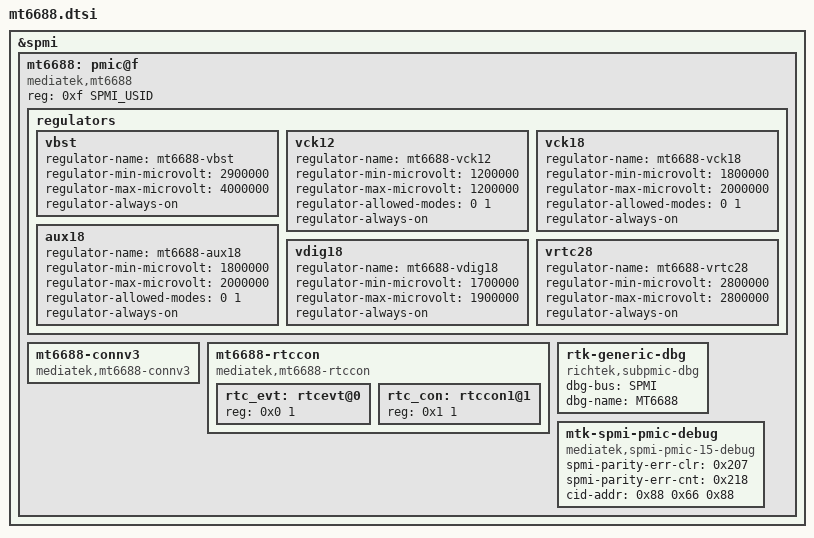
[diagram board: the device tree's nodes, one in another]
// SPDX-License-Identifier: GPL-2.0
/*
 * Copyright (c) 2024 MediaTek Inc.
 */
#include <dt-bindings/spmi/spmi.h>

&spmi {
	mt6688: pmic@f {
		compatible = "mediatek,mt6688";
		reg = <0xf SPMI_USID>;

		regulators {
			vbst {
				regulator-name = "mt6688-vbst";
				regulator-min-microvolt = <2900000>;
				regulator-max-microvolt = <4000000>;
				regulator-always-on;
			};
			vck12 {
				regulator-name = "mt6688-vck12";
				regulator-min-microvolt = <1200000>;
				regulator-max-microvolt = <1200000>;
				regulator-allowed-modes = <0 1>;
				regulator-always-on;
			};
			vck18 {
				regulator-name = "mt6688-vck18";
				regulator-min-microvolt = <1800000>;
				regulator-max-microvolt = <2000000>;
				regulator-allowed-modes = <0 1>;
				regulator-always-on;
			};
			aux18 {
				regulator-name = "mt6688-aux18";
				regulator-min-microvolt = <1800000>;
				regulator-max-microvolt = <2000000>;
				regulator-allowed-modes = <0 1>;
				regulator-always-on;
			};
			vdig18 {
				regulator-name = "mt6688-vdig18";
				regulator-min-microvolt = <1700000>;
				regulator-max-microvolt = <1900000>;
				regulator-always-on;
			};
			vrtc28 {
				regulator-name = "mt6688-vrtc28";
				regulator-min-microvolt = <2800000>;
				regulator-max-microvolt = <2800000>;
				regulator-always-on;
			};
		};

		mt6688-connv3 {
			compatible = "mediatek,mt6688-connv3";
		};

		mt6688-rtccon {
			compatible = "mediatek,mt6688-rtccon";
			#address-cells = <1>;
			#size-cells = <1>;

			rtc_evt: rtcevt@0 {
				reg = <0x0 1>;
			};
			rtc_con: rtccon1@1 {
				reg = <0x1 1>;
			};
		};

		rtk-generic-dbg {
			compatible = "richtek,subpmic-dbg";
			dbg-bus = "SPMI";
			dbg-name = "MT6688";
		};

		mtk-spmi-pmic-debug {
			compatible = "mediatek,spmi-pmic-15-debug";
			spmi-parity-err-clr = <0x207>;
			// spmi-parity-err-sts = <0x2??>; /* E3 feature */
			spmi-parity-err-cnt = <0x218>;
			cid-addr = <0x88 0x66 0x88>;
		};
	};
};
